# nrf54l10_application register map
Vendor: Nordic Semiconductor; Series: nrf54l; File version: 1
CPU: CM33 r0p4, little endian, MPU, FPU, 3 interrupt priority bits, 270 interrupts, 4 SAU regions
Registers are 32-bit, read-write, reset 0x0 unless marked. A register's access mark holds for its fields unless they carry their own. Offsets are from the block's base; [hi:lo] are bit positions; lines under a group give offsets from that group; {n}, {i} and the like mark numbered series; 'fields as' and 'values as' point back to an identical list.

## GLOBAL_FICR_NS — Factory Information Configuration Registers
Base 0x00FFC000
{0x0+8i} CHIPCONF[{i}] (i=0..63) group — Unspecified
  0x00 ADDR ro reset 0xFFFFFFFF — Description cluster: Address of the APB register which will be written
    [31:0] ADDRESS
  0x04 DATA ro reset 0xFFFFFFFF — Description cluster: Data to be written into the APB register
{0x200+0x20*i} DFTENABLE[{i}] (i=0..0) group — DFT Enable Registers
  0x00 PROTECT0 rw-once reset 0xFFFFFFFF — Description cluster: DFT enable register
    [31:0] PALL
      0xDF7EDF7E=Enable (Allow DFT and unlock TAMPC PROTECT.DFT.ENABLE signal protector.)
  {0x4+4j} UNPROTECT0[{j}] (j=0..2) rw-once reset 0xFFFFFFFF — Description collection: DFT enable register o
    [31:0] PALL
      0x50FA50FA=Unprotected, TAMPC is locked for all other values than Unprotected
  {0x10+4j} UNPROTECT1[{j}] (j=0..2) rw-once reset 0xFFFFFFFF — Description collection: DFT enable register o
    fields as DFTENABLE[0].UNPROTECT0[0]
  0x1C PROTECT1 rw-once reset 0xFFFFFFFF — Description cluster: DFT enable register
    fields as DFTENABLE[0].PROTECT0
0x300 INFO group — Device info
  0x00 CONFIGID ro reset 0xFFFFFFFF — Configuration identifier
    [15:0] HWID — Identification number for the HW
  {0x4+4j} DEVICEID[{j}] (j=0..1) ro reset 0xFFFFFFFF — Description collection: Device identifier
    [31:0] DEVICEID — 64 bit unique device identifier
  {0xC+4j} UUID[{j}] (j=0..3) reset 0xFFFFFFFF — Description collection: 128-bit Universally Unique IDentifier (UUID).
    [31:0] UUID — Device UUID [n].
  0x1C PART ro reset 0xFFFFFFFF — Part code
    [31:0] PART
      0x54B15=N54L15 (nRF54L15); 0x54B10=N54L10 (nRF54L10); 0x54B05=N54L05 (nRF54L05); 0xFFFFFFFF=Unspecified
  0x20 VARIANT ro reset 0xFFFFFFFF — Part Variant, Hardware version and Production configuration
    [31:0] VARIANT — Part Variant, Hardware version and Production configuration, encoded as ASCII
      0xFFFFFFFF=Unspecified
  0x24 PACKAGE ro reset 0xFFFFFFFF — Package option
    [31:0] PACKAGE
      0xFFFFFFFF=Unspecified
  0x28 RAM ro reset 0xFFFFFFFF — RAM size (KB)
    [31:0] RAM
      0x100=K256 (256 kByte RAM); 192=K192 (192 kByte RAM); 96=K96 (96 kByte RAM); 0xFFFFFFFF=Unspecified
  0x2C RRAM ro reset 0xFFFFFFFF — RRAM size (KB)
    [31:0] RRAM
      0x5F4=K1524 (1524 KByte RRAM); 0x3F4=K1012 (1012 KByte RRAM); 0x1F4=K500 (500 KByte RRAM); 0xFFFFFFFF=Unspecified
  0x30 DEVICETYPE ro
    [31:0] DEVICETYPE
      0=Die (Device is an physical DIE); 0xFFFFFFFF=FPGA (Device is an FPGA)
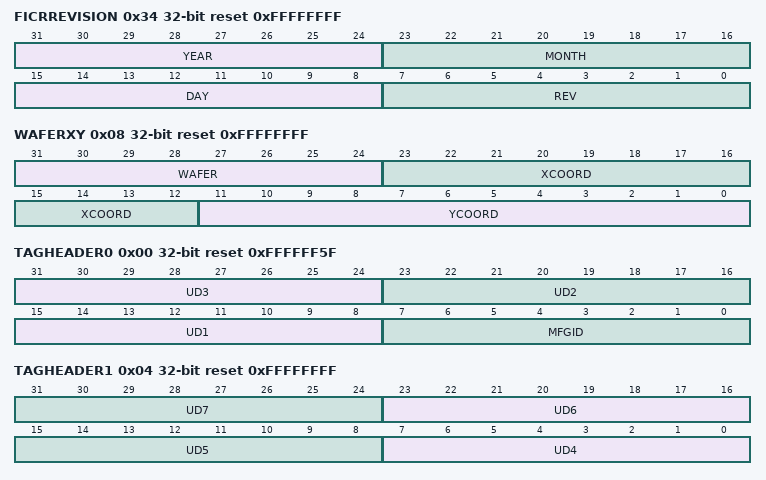
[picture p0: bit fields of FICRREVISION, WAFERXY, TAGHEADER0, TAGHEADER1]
  0x34 FICRREVISION ro reset 0xFFFFFFFF
    [all] fields
      255=Unversioned (Device does not use FICR revision)
    [31:24] YEAR
    [23:16] MONTH
    [15:8] DAY
    [7:0] REV — Incremental number
0x340 SOCINFO group — SOC info. HWREVISION and PARTNO are also part of CHIPCONF array where they are copied to CTRLAPPERI APB registers.
  0x00 PARTNO ro reset 0xFFFFFFFF — Part number of the device.
    [31:0] PARTNO
      28=nRF54L15; 46=nRF54L10; 47=nRF54L05
  0x04 HWREVISION ro reset 0xFFFFFFFF — Hardware Revision of the device. Will be updated in production test.
    [31:0] HWREVISION
      0=SOC1 (Unspecified)
  0x08 PRODUCTIONREVISION ro reset 0xFFFFFFFF — Production revision of the device. Will be updated in production test.
0x350 BOARDINFO ro reset 0xFFFFFFFF — Reserved for board info.
  [31:0] BOARDINFO — Reserved for Nordic use.
{0x380+4i} ER[{i}] (i=0..3) ro reset 0xFFFFFFFF — Description collection: Common encryption root key, word n
  [31:0] ER — Encryption Root, word n
{0x390+4i} IR[{i}] (i=0..3) ro reset 0xFFFFFFFF — Description collection: Common identity root key, word n
  [31:0] IR — Identity Root, word n
0x3A0 DEVICEADDRTYPE ro reset 0xFFFFFFFF — Device address type
  [0] DEVICEADDRTYPE
    0=Public address; 1=Random address
{0x3A4+4i} DEVICEADDR[{i}] (i=0..1) ro reset 0xFFFFFFFF — Description collection: Device address n
  [31:0] DEVICEADDR — 48 bit device address
0x3B0 PROTEST group — Production test information
  0x00 CP group — Unspecified
    {0x0+4k} LOTNR[{k}] (k=0..1) ro reset 0xFFFFFFFF — Description collection: Lot number.
      [31:0] LOTNR — Lot number
    0x08 WAFERXY ro reset 0xFFFFFFFF — Wafer number and die X,Y coordinate.
      [31:24] WAFER — Wafer number
      [23:12] XCOORD — Die x coordinate
      [11:0] YCOORD — Die y coordinate
    0x0C PROGVERSION1 ro reset 0xFFFFFFFF — CP1 test program version.
      [31:0] VAL — CP1 test program version
    0x10 PROGVERSION2 ro reset 0xFFFFFFFF — CP2 test program version.
      [31:0] VAL — CP2 test program version
    0x14 PASSID1 ro reset 0xFFFFFFFF — CP1 pass ID.
      [31:0] VAL
    0x18 PASSID2 ro reset 0xFFFFFFFF — CP2 pass ID.
      [31:0] VAL
    0x1C TIMESTAMP1 ro reset 0xFFFFFFFF — Timestamp for when CP1 starts or ends (YYYYMMDDTHHMMSS)
      [31:0] VAL — CP1 timestamp
    0x20 TIMESTAMP2 ro reset 0xFFFFFFFF — Timestamp for when CP2 starts or ends (YYYYMMDDTHHMMSS)
      [31:0] VAL — CP2 timestamp
  0x24 FT group — Unspecified
    0x00 PROGVERSION1 ro reset 0xFFFFFFFF — FT1 test program version.
      [31:0] PROGVERSION1 — FT1 test program version
    0x04 PROGVERSION2 ro reset 0xFFFFFFFF — FT2/EQA test program version.
      [31:0] PROGVERSION2 — FT2/EQA test program version
    0x08 PASSID1 ro reset 0xFFFFFFFF — FT1 pass ID.
      [31:0] VAL
    0x0C PASSID2 ro reset 0xFFFFFFFF — FT2/EQA pass ID.
      [31:0] VAL
    0x10 TIMESTAMP1 ro reset 0xFFFFFFFF — Timestamp for when FT1 starts or ends (YYYYMMDDTHHMMSS)
      [31:0] VAL — FT1 timestamp
    0x14 TIMESTAMP2 ro reset 0xFFFFFFFF — Timestamp for when FT2/EQA starts or ends (YYYYMMDDTHHMMSS)
      [31:0] VAL — FT2/EQA timestamp
{0x400+8i} TRIMCNF[{i}] (i=0..63) group — Unspecified
  0x00 ADDR ro reset 0xFFFFFFFF — Description cluster: Address of the register which will be written
    [31:0] Address
  0x04 DATA ro reset 0xFFFFFFFF — Description cluster: Data to be written into the register
0x600 NFC group — Unspecified
  0x00 TAGHEADER0 ro reset 0xFFFFFF5F — Default header for NFC Tag. Software can read these values to populate NFCID1_3RD_LAST, NFCID1_2ND_LAST and NFCID1_LAST.
    [31:24] UD3 — Unique identifier byte 3
    [23:16] UD2 — Unique identifier byte 2
    [15:8] UD1 — Unique identifier byte 1
    [7:0] MFGID — Default Manufacturer ID: Nordic Semiconductor ASA has ICM 0x5F
  0x04 TAGHEADER1 ro reset 0xFFFFFFFF — Default header for NFC Tag. Software can read these values to populate NFCID1_3RD_LAST, NFCID1_2ND_LAST and NFCID1_LAST.
    [8n-25:8n-32] UD{n} (n=4..7) — Unique identifier byte {n}
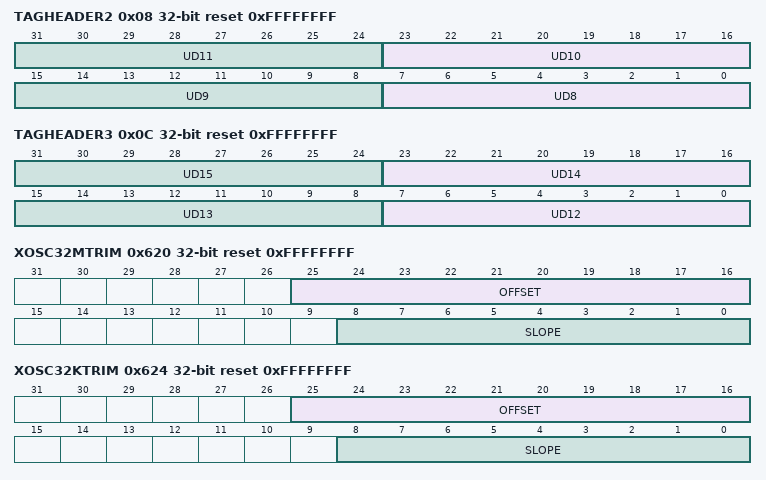
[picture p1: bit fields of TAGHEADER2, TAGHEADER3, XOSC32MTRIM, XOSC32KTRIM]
  0x08 TAGHEADER2 ro reset 0xFFFFFFFF — Default header for NFC Tag. Software can read these values to populate NFCID1_3RD_LAST, NFCID1_2ND_LAST and NFCID1_LAST.
    [8n-57:8n-64] UD{n} (n=8..11) — Unique identifier byte {n}
  0x0C TAGHEADER3 ro reset 0xFFFFFFFF — Default header for NFC Tag. Software can read these values to populate NFCID1_3RD_LAST, NFCID1_2ND_LAST and NFCID1_LAST.
    [8n-89:8n-96] UD{n} (n=12..15) — Unique identifier byte {n}
0x620 XOSC32MTRIM ro reset 0xFFFFFFFF — XOSC32M capacitor selection trim values
  [25:16] OFFSET — Offset trim factor on integer form
  [8:0] SLOPE — Slope trim factor on twos complement form
0x624 XOSC32KTRIM ro reset 0xFFFFFFFF — XOSC32K capacitor selection trim values
  fields as XOSC32MTRIM
0xC00 OTP group — Unspecified
  {0x0+0x10*j} PRODUCTION1[{j}] (j=0..1) group — OTP Production Registers
    {0x0+4k} UNPROTECT[{k}] (k=0..3) rw-once reset 0xFFFFFFFF — Description collection: OTP protection registers for DFT enabling/disabling
      [31:0] PALL
  {0x20+0x10*j} PRODUCTION2[{j}] (j=0..1) group — OTP Production Registers
    {0x0+4k} UNPROTECT[{k}] (k=0..3) rw-once reset 0xFFFFFFFF — Description collection: OTP protection registers for DFT enabling/disabling
      [31:0] PALL

## Notices in the file
Copyright (c) 2010 - 2025, Nordic Semiconductor ASA
All rights reserved.
Redistribution and use in source and binary forms, with or without modification,
are permitted provided that the following conditions are met:
1. Redistributions of source code must retain the above copyright notice, this
list of conditions and the following disclaimer.
2. Redistributions in binary form, except as embedded into a Nordic
Semiconductor ASA integrated circuit in a product or a software update for
such product, must reproduce the above copyright notice, this list of
conditions and the following disclaimer in the documentation and/or other
materials provided with the distribution.
3. Neither the name of Nordic Semiconductor ASA nor the names of its
contributors may be used to endorse or promote products derived from this
software without specific prior written permission.
4. This software, with or without modification, must only be used with a
Nordic Semiconductor ASA integrated circuit.
5. Any software provided in binary form under this license must not be reverse
engineered, decompiled, modified and/or disassembled.
THIS SOFTWARE IS PROVIDED BY NORDIC SEMICONDUCTOR ASA "AS IS" AND ANY EXPRESS
OR IMPLIED WARRANTIES, INCLUDING, BUT NOT LIMITED TO, THE IMPLIED WARRANTIES
OF MERCHANTABILITY, NONINFRINGEMENT, AND FITNESS FOR A PARTICULAR PURPOSE ARE
DISCLAIMED. IN NO EVENT SHALL NORDIC SEMICONDUCTOR ASA OR CONTRIBUTORS BE
LIABLE FOR ANY DIRECT, INDIRECT, INCIDENTAL, SPECIAL, EXEMPLARY, OR
CONSEQUENTIAL DAMAGES (INCLUDING, BUT NOT LIMITED TO, PROCUREMENT OF SUBSTITUTE
GOODS OR SERVICES; LOSS OF USE, DATA, OR PROFITS; OR BUSINESS INTERRUPTION)
HOWEVER CAUSED AND ON ANY THEORY OF LIABILITY, WHETHER IN CONTRACT, STRICT
LIABILITY, OR TORT (INCLUDING NEGLIGENCE OR OTHERWISE) ARISING IN ANY WAY OUT
OF THE USE OF THIS SOFTWARE, EVEN IF ADVISED OF THE POSSIBILITY OF SUCH DAMAGE.
